AUTOSAR XML (schema 4-0-3)
package /AUTOSAR_Dcm/SwComponentTypes
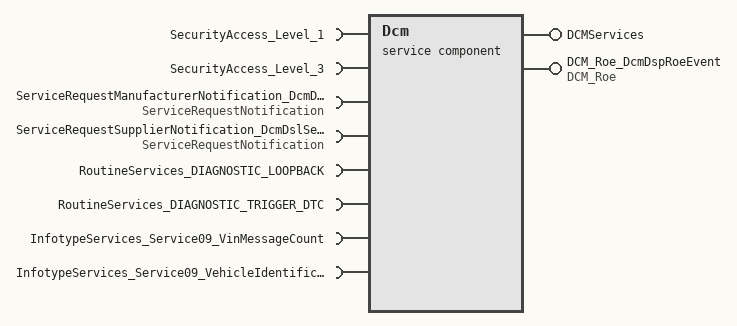
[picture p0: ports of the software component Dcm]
  service sw component type Dcm
    provide port DCMServices: provided-interface=DCMServices
      provided-com-specs:
        operation=GetSecurityLevel, queue-length=1
        operation=GetSesCtrlType, queue-length=1
        operation=GetActiveProtocol, queue-length=1
        operation=ResetToDefaultSession, queue-length=1
    provide port DCM_Roe_DcmDspRoeEvent: server-com-spec{operation=TriggerOnEvent, queue-length=1}, provided-interface=DCM_Roe
    8 x require port:
      SecurityAccess_Level_1: required-interface=SecurityAccess_Level_1
      SecurityAccess_Level_3: required-interface=SecurityAccess_Level_3
      ServiceRequestManufacturerNotification_DcmDslServiceRequestManufacturerNotification_0: required-interface=ServiceRequestNotification
      ServiceRequestSupplierNotification_DcmDslServiceRequestSupplierNotification_0: required-interface=ServiceRequestNotification
      RoutineServices_DIAGNOSTIC_LOOPBACK: required-interface=RoutineServices_DIAGNOSTIC_LOOPBACK
      RoutineServices_DIAGNOSTIC_TRIGGER_DTC: required-interface=RoutineServices_DIAGNOSTIC_TRIGGER_DTC
      InfotypeServices_Service09_VinMessageCount: required-interface=InfotypeServices_Service09_VinMessageCount
      InfotypeServices_Service09_VehicleIdentificationNumber: required-interface=InfotypeServices_Service09_VehicleIdentificationNumber
    behavior DcmIntBeh: handle-termination-and-restart=NO-SUPPORT, included-data-type-set=data-type=[Dcm_DidSupportedType, Dcm_ConfirmationStatusType, Dcm_OpStatusType, Dcm_NegativeResponseCodeType]
      5 x operation invoked event:
        EV_GetSecurityLevel: start-on-event=RE_GetSecurityLevel, operation=DCMServices.GetSecurityLevel
        EV_GetSesCtrlType: start-on-event=RE_GetSesCtrlType, operation=DCMServices.GetSesCtrlType
        EV_GetActiveProtocol: start-on-event=RE_GetActiveProtocol, operation=DCMServices.GetActiveProtocol
        EV_ResetToDefaultSession: start-on-event=RE_ResetToDefaultSession, operation=DCMServices.ResetToDefaultSession
        EV_TriggerOnEvent_DcmDspRoeEvent: start-on-event=RE_TriggerOnEvent, operation=DCM_Roe_DcmDspRoeEvent.TriggerOnEvent
      port-api-options:
        enable-take-address=true, indirect-api=false, port=SecurityAccess_Level_1
        enable-take-address=true, indirect-api=false, port=SecurityAccess_Level_3
        enable-take-address=true, indirect-api=false, port=ServiceRequestManufacturerNotification_DcmDslServiceRequestManufacturerNotification_0
        enable-take-address=true, indirect-api=false, port=ServiceRequestSupplierNotification_DcmDslServiceRequestSupplierNotification_0
        enable-take-address=true, indirect-api=false, port=RoutineServices_DIAGNOSTIC_LOOPBACK
        enable-take-address=true, indirect-api=false, port=RoutineServices_DIAGNOSTIC_TRIGGER_DTC
        {enable-take-address=false, indirect-api=false, port-defined-argument-value{value=0, value-type=uint8}, port=DCM_Roe_DcmDspRoeEvent}
        enable-take-address=true, indirect-api=false, port=InfotypeServices_Service09_VinMessageCount
        enable-take-address=true, indirect-api=false, port=InfotypeServices_Service09_VehicleIdentificationNumber
      6 x runnable, all with sw-addr-method=CODE:
        RE_GetSecurityLevel: can-be-invoked-concurrently=true, symbol=Dcm_GetSecurityLevel
        RE_GetSesCtrlType: can-be-invoked-concurrently=true, symbol=Dcm_GetSesCtrlType
        RE_GetActiveProtocol: can-be-invoked-concurrently=true, symbol=Dcm_GetActiveProtocol
        RE_ResetToDefaultSession: can-be-invoked-concurrently=true, symbol=Dcm_ResetToDefaultSession
        RE_TriggerOnEvent: runnable-entity-argument=symbol=RoeEventId, can-be-invoked-concurrently=true, symbol=Dcm_TriggerOnEvent
        RE_MainFunction: symbol=Dcm_MainFunction
          12 x sync call, all with timeout=0.0:
            sscp_SecurityAccessGetSeed_Level_1: operation=SecurityAccess_Level_1.GetSeed
            sscp_SecurityAccessCompareKey_Level_1: operation=SecurityAccess_Level_1.CompareKey
            sscp_SecurityAccessGetSeed_Level_3: operation=SecurityAccess_Level_3.GetSeed
            sscp_SecurityAccessCompareKey_Level_3: operation=SecurityAccess_Level_3.CompareKey
            sscp_InfotypeServicesGetInfotypeValueData_Service09_VinMessageCount: operation=InfotypeServices_Service09_VinMessageCount.GetInfotypeValueData
            sscp_InfotypeServicesGetInfotypeValueData_Service09_VehicleIdentificationNumber: operation=InfotypeServices_Service09_VehicleIdentificationNumber.GetInfotypeValueData
            sscp_ServiceRequestManufacturerNotificationIndication_DcmDslServiceRequestManufacturerNotification_0: operation=ServiceRequestManufacturerNotification_DcmDslServiceRequestManufacturerNotification_0.Indication
            sscp_ServiceRequestManufacturerNotificationConfirmation_DcmDslServiceRequestManufacturerNotification_0: operation=ServiceRequestManufacturerNotification_DcmDslServiceRequestManufacturerNotification_0.Confirmation
            sscp_ServiceRequestSupplierNotificationIndication_DcmDslServiceRequestSupplierNotification_0: operation=ServiceRequestSupplierNotification_DcmDslServiceRequestSupplierNotification_0.Indication
            sscp_ServiceRequestSupplierNotificationConfirmation_DcmDslServiceRequestSupplierNotification_0: operation=ServiceRequestSupplierNotification_DcmDslServiceRequestSupplierNotification_0.Confirmation
            sscp_RoutineServicesStart_DIAGNOSTIC_LOOPBACK: operation=RoutineServices_DIAGNOSTIC_LOOPBACK.Start
            sscp_RoutineServicesStart_DIAGNOSTIC_TRIGGER_DTC: operation=RoutineServices_DIAGNOSTIC_TRIGGER_DTC.Start
package /EB_Dcm/SwcImplementations
  swc implementation DcmImpl: programming-language=C, sw-version=5.0.13, vendor-id=1, behavior=DcmIntBeh
    code-descriptors:
      code Code: artifact-descriptors=autosar-engineering-object={short-label=EngObject, category=SWSRC}
    resource consumption Resources
      memory section CODE: sw-addrmethod=CODE
